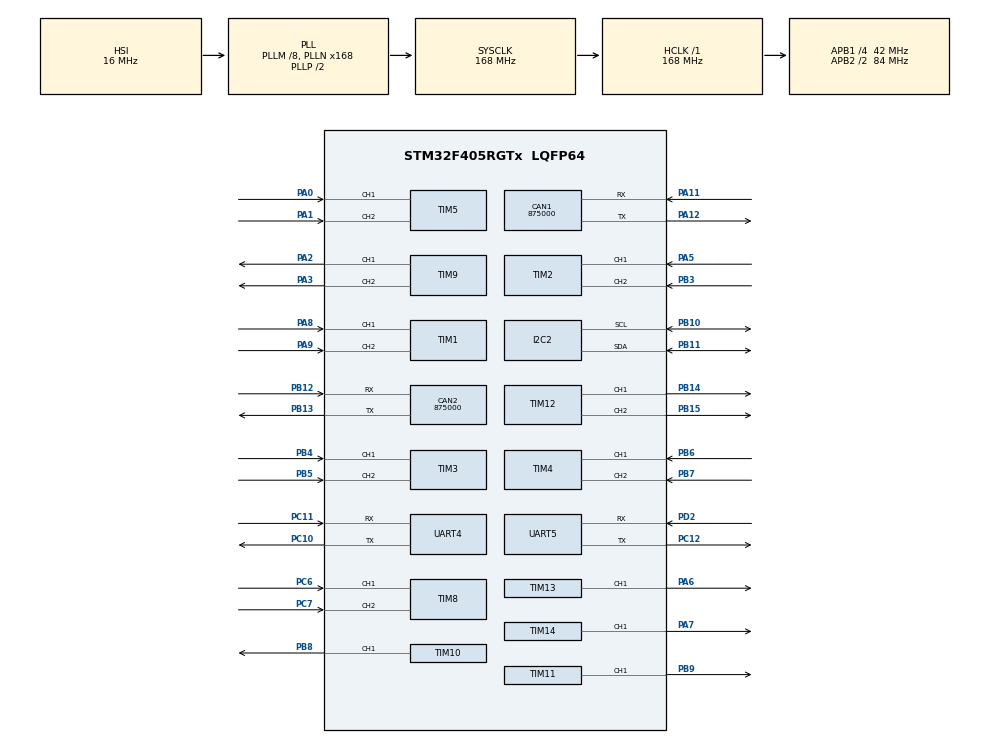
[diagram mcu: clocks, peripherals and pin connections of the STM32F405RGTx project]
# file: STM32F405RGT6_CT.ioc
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CAN1.CalculateBaudRate=875000
CAN1.CalculateTimeBit=1142
CAN1.CalculateTimeQuantum=380.95238095238096
CAN2.CalculateBaudRate=875000
CAN2.CalculateTimeBit=1142
CAN2.CalculateTimeQuantum=380.95238095238096
FREERTOS.Tasks01=defaultTask,24,128,StartDefaultTask,Default,NULL,Dynamic,NULL,NULL
Mcu.Family=STM32F4
Mcu.Name=STM32F405RGTx
Mcu.Package=LQFP64
NVIC.PriorityGroup=NVIC_PRIORITYGROUP_4
NVIC.TIM6_DAC_IRQn=true\:15\:0\:false\:false\:true\:false\:false\:true\:true
NVIC.TimeBase=TIM6_DAC_IRQn
NVIC.TimeBaseIP=TIM6
PA0-WKUP.Signal=S_TIM5_CH1
PA1.Signal=S_TIM5_CH2
PA11.Mode=CAN_Activate
PA11.Signal=CAN1_RX
PA12.Mode=CAN_Activate
PA12.Signal=CAN1_TX
PA13.Mode=Serial_Wire
PA13.Signal=SYS_JTMS-SWDIO
PA14.Mode=Serial_Wire
PA14.Signal=SYS_JTCK-SWCLK
PA2.Signal=S_TIM9_CH1
PA3.Signal=S_TIM9_CH2
PA5.Signal=S_TIM2_CH1_ETR
PA6.Signal=S_TIM13_CH1
PA7.Signal=S_TIM14_CH1
PA8.Signal=S_TIM1_CH1
PA9.Signal=S_TIM1_CH2
PB10.Mode=I2C
PB10.Signal=I2C2_SCL
PB11.Mode=I2C
PB11.Signal=I2C2_SDA
PB12.Mode=CAN_Activate
PB12.Signal=CAN2_RX
PB13.Mode=CAN_Activate
PB13.Signal=CAN2_TX
PB14.Signal=S_TIM12_CH1
PB15.Signal=S_TIM12_CH2
PB3.Signal=S_TIM2_CH2
PB4.Signal=S_TIM3_CH1
PB5.Signal=S_TIM3_CH2
PB6.Signal=S_TIM4_CH1
PB7.Signal=S_TIM4_CH2
PB8.Signal=S_TIM10_CH1
PB9.Signal=S_TIM11_CH1
PC10.Mode=Asynchronous
PC10.Signal=UART4_TX
PC11.Mode=Asynchronous
PC11.Signal=UART4_RX
PC12.Mode=Asynchronous
PC12.Signal=UART5_TX
PC6.Signal=S_TIM8_CH1
PC7.Signal=S_TIM8_CH2
PD2.Mode=Asynchronous
PD2.Signal=UART5_RX
PH0-OSC_IN.Mode=HSE-External-Oscillator
PH0-OSC_IN.Signal=RCC_OSC_IN
PH1-OSC_OUT.Mode=HSE-External-Oscillator
PH1-OSC_OUT.Signal=RCC_OSC_OUT
ProjectManager.HeapSize=0x200
ProjectManager.StackSize=0x400
ProjectManager.TargetToolchain=CMake
RCC.48MHZClocksFreq_Value=84000000
RCC.AHBFreq_Value=168000000
RCC.APB1CLKDivider=RCC_HCLK_DIV4
RCC.APB1Freq_Value=42000000
RCC.APB1TimFreq_Value=84000000
RCC.APB2CLKDivider=RCC_HCLK_DIV2
RCC.APB2Freq_Value=84000000
RCC.APB2TimFreq_Value=168000000
RCC.CortexFreq_Value=168000000
RCC.HCLKFreq_Value=168000000
RCC.HSE_VALUE=8000000
RCC.HSI_VALUE=16000000
RCC.LSE_VALUE=32768
RCC.PLLM=8
RCC.PLLN=168
RCC.SYSCLKFreq_VALUE=168000000
RCC.SYSCLKSource=RCC_SYSCLKSOURCE_PLLCLK
RCC.VCOOutputFreq_Value=336000000
SH.S_TIM10_CH1.0=TIM10_CH1,PWM Generation1 CH1
SH.S_TIM11_CH1.0=TIM11_CH1,PWM Generation1 CH1
SH.S_TIM12_CH1.0=TIM12_CH1,PWM Generation1 CH1
SH.S_TIM12_CH2.0=TIM12_CH2,PWM Generation2 CH2
SH.S_TIM13_CH1.0=TIM13_CH1,PWM Generation1 CH1
SH.S_TIM14_CH1.0=TIM14_CH1,PWM Generation1 CH1
SH.S_TIM1_CH1.0=TIM1_CH1,Encoder_Interface
SH.S_TIM1_CH2.0=TIM1_CH2,Encoder_Interface
SH.S_TIM2_CH1_ETR.0=TIM2_CH1,Encoder_Interface
SH.S_TIM2_CH2.0=TIM2_CH2,Encoder_Interface
SH.S_TIM3_CH1.0=TIM3_CH1,Encoder_Interface
SH.S_TIM3_CH2.0=TIM3_CH2,Encoder_Interface
SH.S_TIM4_CH1.0=TIM4_CH1,Encoder_Interface
SH.S_TIM4_CH2.0=TIM4_CH2,Encoder_Interface
SH.S_TIM5_CH1.0=TIM5_CH1,Encoder_Interface
SH.S_TIM5_CH2.0=TIM5_CH2,Encoder_Interface
SH.S_TIM8_CH1.0=TIM8_CH1,Encoder_Interface
SH.S_TIM8_CH2.0=TIM8_CH2,Encoder_Interface
SH.S_TIM9_CH1.0=TIM9_CH1,PWM Generation1 CH1
SH.S_TIM9_CH2.0=TIM9_CH2,PWM Generation2 CH2
TIM10.Channel=TIM_CHANNEL_1
TIM11.Channel=TIM_CHANNEL_1
TIM12.Channel-PWM\ Generation1\ CH1=TIM_CHANNEL_1
TIM12.Channel-PWM\ Generation2\ CH2=TIM_CHANNEL_2
TIM13.Channel=TIM_CHANNEL_1
TIM14.Channel=TIM_CHANNEL_1
TIM9.Channel-PWM\ Generation1\ CH1=TIM_CHANNEL_1
TIM9.Channel-PWM\ Generation2\ CH2=TIM_CHANNEL_2
UART4.VirtualMode=Asynchronous
UART5.VirtualMode=Asynchronous
VP_FREERTOS_VS_CMSIS_V2.Mode=CMSIS_V2
VP_SYS_VS_tim6.Mode=TIM6
VP_TIM10_VS_ClockSourceINT.Mode=Enable_Timer
VP_TIM11_VS_ClockSourceINT.Mode=Enable_Timer
VP_TIM12_VS_ClockSourceINT.Mode=Internal
VP_TIM13_VS_ClockSourceINT.Mode=Enable_Timer
VP_TIM14_VS_ClockSourceINT.Mode=Enable_Timer
VP_TIM9_VS_ClockSourceINT.Mode=Internal
board=custom

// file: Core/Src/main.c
/* USER CODE BEGIN Header */
/**
  ******************************************************************************
  * @file           : main.c
  * @brief          : Main program body
  ******************************************************************************
  * @attention
  *
  * Copyright (c) 2026 STMicroelectronics.
  * All rights reserved.
  *
  * This software is licensed under terms that can be found in the LICENSE file
  * in the root directory of this software component.
  * If no LICENSE file comes with this software, it is provided AS-IS.
  *
  ******************************************************************************
  */
/* USER CODE END Header */
#include "main.h"
#include "cmsis_os.h"

CAN_HandleTypeDef hcan1;
CAN_HandleTypeDef hcan2;

I2C_HandleTypeDef hi2c2;

TIM_HandleTypeDef htim1;
TIM_HandleTypeDef htim2;
TIM_HandleTypeDef htim3;
TIM_HandleTypeDef htim4;
TIM_HandleTypeDef htim5;
TIM_HandleTypeDef htim8;
TIM_HandleTypeDef htim9;
TIM_HandleTypeDef htim10;
TIM_HandleTypeDef htim11;
TIM_HandleTypeDef htim12;
TIM_HandleTypeDef htim13;
TIM_HandleTypeDef htim14;

UART_HandleTypeDef huart4;
UART_HandleTypeDef huart5;

/* Definitions for defaultTask */
osThreadId_t defaultTaskHandle;
const osThreadAttr_t defaultTask_attributes = {
  .name = "defaultTask",
  .stack_size = 128 * 4,
  .priority = (osPriority_t) osPriorityNormal,
};

void SystemClock_Config(void);
static void MX_GPIO_Init(void);
static void MX_CAN1_Init(void);
static void MX_CAN2_Init(void);
static void MX_I2C2_Init(void);
static void MX_TIM1_Init(void);
static void MX_TIM2_Init(void);
static void MX_TIM3_Init(void);
static void MX_TIM4_Init(void);
static void MX_TIM5_Init(void);
static void MX_TIM8_Init(void);
static void MX_TIM9_Init(void);
static void MX_TIM10_Init(void);
static void MX_TIM11_Init(void);
static void MX_TIM12_Init(void);
static void MX_TIM13_Init(void);
static void MX_TIM14_Init(void);
static void MX_UART4_Init(void);
static void MX_UART5_Init(void);
void StartDefaultTask(void *argument);

int main(void)
{

  /* MCU Configuration--------------------------------------------------------*/

  /* Reset of all peripherals, Initializes the Flash interface and the Systick. */
  HAL_Init();

  /* Configure the system clock */
  SystemClock_Config();

  /* Initialize all configured peripherals */
  MX_GPIO_Init();
  MX_CAN1_Init();
  MX_CAN2_Init();
  MX_I2C2_Init();
  MX_TIM1_Init();
  MX_TIM2_Init();
  MX_TIM3_Init();
  MX_TIM4_Init();
  MX_TIM5_Init();
  MX_TIM8_Init();
  MX_TIM9_Init();
  MX_TIM10_Init();
  MX_TIM11_Init();
  MX_TIM12_Init();
  MX_TIM13_Init();
  MX_TIM14_Init();
  MX_UART4_Init();
  MX_UART5_Init();

  /* Init scheduler */
  osKernelInitialize();

  /* Create the thread(s) */
  /* creation of defaultTask */
  defaultTaskHandle = osThreadNew(StartDefaultTask, NULL, &defaultTask_attributes);

  /* Start scheduler */
  osKernelStart();

  /* We should never get here as control is now taken by the scheduler */

  /* Infinite loop */
  /* USER CODE BEGIN WHILE */
  while (1)
  {
    HAL_GPIO_TogglePin(GPIOC, GPIO_PIN_13);
    HAL_Delay(500);
    /* USER CODE END WHILE */

  }
}

void SystemClock_Config(void)
{
  RCC_OscInitTypeDef RCC_OscInitStruct = {0};
  RCC_ClkInitTypeDef RCC_ClkInitStruct = {0};

  /** Configure the main internal regulator output voltage
  */
  __HAL_RCC_PWR_CLK_ENABLE();
  __HAL_PWR_VOLTAGESCALING_CONFIG(PWR_REGULATOR_VOLTAGE_SCALE1);

  /** Initializes the RCC Oscillators according to the specified parameters
  * in the RCC_OscInitTypeDef structure.
  */
  RCC_OscInitStruct.OscillatorType = RCC_OSCILLATORTYPE_HSI;
  RCC_OscInitStruct.HSIState = RCC_HSI_ON;
  RCC_OscInitStruct.HSICalibrationValue = RCC_HSICALIBRATION_DEFAULT;
  RCC_OscInitStruct.PLL.PLLState = RCC_PLL_ON;
  RCC_OscInitStruct.PLL.PLLSource = RCC_PLLSOURCE_HSI;
  RCC_OscInitStruct.PLL.PLLM = 8;
  RCC_OscInitStruct.PLL.PLLN = 168;
  RCC_OscInitStruct.PLL.PLLP = RCC_PLLP_DIV2;
  RCC_OscInitStruct.PLL.PLLQ = 4;
  if (HAL_RCC_OscConfig(&RCC_OscInitStruct) != HAL_OK)
  {
    Error_Handler();
  }

  /** Initializes the CPU, AHB and APB buses clocks
  */
  RCC_ClkInitStruct.ClockType = RCC_CLOCKTYPE_HCLK|RCC_CLOCKTYPE_SYSCLK
                              |RCC_CLOCKTYPE_PCLK1|RCC_CLOCKTYPE_PCLK2;
  RCC_ClkInitStruct.SYSCLKSource = RCC_SYSCLKSOURCE_PLLCLK;
  RCC_ClkInitStruct.AHBCLKDivider = RCC_SYSCLK_DIV1;
  RCC_ClkInitStruct.APB1CLKDivider = RCC_HCLK_DIV4;
  RCC_ClkInitStruct.APB2CLKDivider = RCC_HCLK_DIV2;

  if (HAL_RCC_ClockConfig(&RCC_ClkInitStruct, FLASH_LATENCY_5) != HAL_OK)
  {
    Error_Handler();
  }
}

static void MX_CAN1_Init(void)
{

  hcan1.Instance = CAN1;
  hcan1.Init.Prescaler = 16;
  hcan1.Init.Mode = CAN_MODE_NORMAL;
  hcan1.Init.SyncJumpWidth = CAN_SJW_1TQ;
  hcan1.Init.TimeSeg1 = CAN_BS1_1TQ;
  hcan1.Init.TimeSeg2 = CAN_BS2_1TQ;
  hcan1.Init.TimeTriggeredMode = DISABLE;
  hcan1.Init.AutoBusOff = DISABLE;
  hcan1.Init.AutoWakeUp = DISABLE;
  hcan1.Init.AutoRetransmission = DISABLE;
  hcan1.Init.ReceiveFifoLocked = DISABLE;
  hcan1.Init.TransmitFifoPriority = DISABLE;
  if (HAL_CAN_Init(&hcan1) != HAL_OK)
  {
    Error_Handler();
  }

}

static void MX_CAN2_Init(void)
{

  hcan2.Instance = CAN2;
  hcan2.Init.Prescaler = 16;
  hcan2.Init.Mode = CAN_MODE_NORMAL;
  hcan2.Init.SyncJumpWidth = CAN_SJW_1TQ;
  hcan2.Init.TimeSeg1 = CAN_BS1_1TQ;
  hcan2.Init.TimeSeg2 = CAN_BS2_1TQ;
  hcan2.Init.TimeTriggeredMode = DISABLE;
  hcan2.Init.AutoBusOff = DISABLE;
  hcan2.Init.AutoWakeUp = DISABLE;
  hcan2.Init.AutoRetransmission = DISABLE;
  hcan2.Init.ReceiveFifoLocked = DISABLE;
  hcan2.Init.TransmitFifoPriority = DISABLE;
  if (HAL_CAN_Init(&hcan2) != HAL_OK)
  {
    Error_Handler();
  }

}

static void MX_I2C2_Init(void)
{

  hi2c2.Instance = I2C2;
  hi2c2.Init.ClockSpeed = 100000;
  hi2c2.Init.DutyCycle = I2C_DUTYCYCLE_2;
  hi2c2.Init.OwnAddress1 = 0;
  hi2c2.Init.AddressingMode = I2C_ADDRESSINGMODE_7BIT;
  hi2c2.Init.DualAddressMode = I2C_DUALADDRESS_DISABLE;
  hi2c2.Init.OwnAddress2 = 0;
  hi2c2.Init.GeneralCallMode = I2C_GENERALCALL_DISABLE;
  hi2c2.Init.NoStretchMode = I2C_NOSTRETCH_DISABLE;
  if (HAL_I2C_Init(&hi2c2) != HAL_OK)
  {
    Error_Handler();
  }

}

static void MX_TIM1_Init(void)
{

  TIM_Encoder_InitTypeDef sConfig = {0};
  TIM_MasterConfigTypeDef sMasterConfig = {0};

  htim1.Instance = TIM1;
  htim1.Init.Prescaler = 0;
  htim1.Init.CounterMode = TIM_COUNTERMODE_UP;
  htim1.Init.Period = 65535;
  htim1.Init.ClockDivision = TIM_CLOCKDIVISION_DIV1;
  htim1.Init.RepetitionCounter = 0;
  htim1.Init.AutoReloadPreload = TIM_AUTORELOAD_PRELOAD_DISABLE;
  sConfig.EncoderMode = TIM_ENCODERMODE_TI1;
  sConfig.IC1Polarity = TIM_ICPOLARITY_RISING;
  sConfig.IC1Selection = TIM_ICSELECTION_DIRECTTI;
  sConfig.IC1Prescaler = TIM_ICPSC_DIV1;
  sConfig.IC1Filter = 0;
  sConfig.IC2Polarity = TIM_ICPOLARITY_RISING;
  sConfig.IC2Selection = TIM_ICSELECTION_DIRECTTI;
  sConfig.IC2Prescaler = TIM_ICPSC_DIV1;
  sConfig.IC2Filter = 0;
  if (HAL_TIM_Encoder_Init(&htim1, &sConfig) != HAL_OK)
  {
    Error_Handler();
  }
  sMasterConfig.MasterOutputTrigger = TIM_TRGO_RESET;
  sMasterConfig.MasterSlaveMode = TIM_MASTERSLAVEMODE_DISABLE;
  if (HAL_TIMEx_MasterConfigSynchronization(&htim1, &sMasterConfig) != HAL_OK)
  {
    Error_Handler();
  }

}

static void MX_TIM2_Init(void)
{

  TIM_Encoder_InitTypeDef sConfig = {0};
  TIM_MasterConfigTypeDef sMasterConfig = {0};

  htim2.Instance = TIM2;
  htim2.Init.Prescaler = 0;
  htim2.Init.CounterMode = TIM_COUNTERMODE_UP;
  htim2.Init.Period = 4294967295;
  htim2.Init.ClockDivision = TIM_CLOCKDIVISION_DIV1;
  htim2.Init.AutoReloadPreload = TIM_AUTORELOAD_PRELOAD_DISABLE;
  sConfig.EncoderMode = TIM_ENCODERMODE_TI1;
  sConfig.IC1Polarity = TIM_ICPOLARITY_RISING;
  sConfig.IC1Selection = TIM_ICSELECTION_DIRECTTI;
  sConfig.IC1Prescaler = TIM_ICPSC_DIV1;
  sConfig.IC1Filter = 0;
  sConfig.IC2Polarity = TIM_ICPOLARITY_RISING;
  sConfig.IC2Selection = TIM_ICSELECTION_DIRECTTI;
  sConfig.IC2Prescaler = TIM_ICPSC_DIV1;
  sConfig.IC2Filter = 0;
  if (HAL_TIM_Encoder_Init(&htim2, &sConfig) != HAL_OK)
  {
    Error_Handler();
  }
  sMasterConfig.MasterOutputTrigger = TIM_TRGO_RESET;
  sMasterConfig.MasterSlaveMode = TIM_MASTERSLAVEMODE_DISABLE;
  if (HAL_TIMEx_MasterConfigSynchronization(&htim2, &sMasterConfig) != HAL_OK)
  {
    Error_Handler();
  }

}

static void MX_TIM3_Init(void)
{

  TIM_Encoder_InitTypeDef sConfig = {0};
  TIM_MasterConfigTypeDef sMasterConfig = {0};

  htim3.Instance = TIM3;
  htim3.Init.Prescaler = 0;
  htim3.Init.CounterMode = TIM_COUNTERMODE_UP;
  htim3.Init.Period = 65535;
  htim3.Init.ClockDivision = TIM_CLOCKDIVISION_DIV1;
  htim3.Init.AutoReloadPreload = TIM_AUTORELOAD_PRELOAD_DISABLE;
  sConfig.EncoderMode = TIM_ENCODERMODE_TI1;
  sConfig.IC1Polarity = TIM_ICPOLARITY_RISING;
  sConfig.IC1Selection = TIM_ICSELECTION_DIRECTTI;
  sConfig.IC1Prescaler = TIM_ICPSC_DIV1;
  sConfig.IC1Filter = 0;
  sConfig.IC2Polarity = TIM_ICPOLARITY_RISING;
  sConfig.IC2Selection = TIM_ICSELECTION_DIRECTTI;
  sConfig.IC2Prescaler = TIM_ICPSC_DIV1;
  sConfig.IC2Filter = 0;
  if (HAL_TIM_Encoder_Init(&htim3, &sConfig) != HAL_OK)
  {
    Error_Handler();
  }
  sMasterConfig.MasterOutputTrigger = TIM_TRGO_RESET;
  sMasterConfig.MasterSlaveMode = TIM_MASTERSLAVEMODE_DISABLE;
  if (HAL_TIMEx_MasterConfigSynchronization(&htim3, &sMasterConfig) != HAL_OK)
  {
    Error_Handler();
  }

}

static void MX_TIM4_Init(void)
{

  TIM_Encoder_InitTypeDef sConfig = {0};
  TIM_MasterConfigTypeDef sMasterConfig = {0};

  htim4.Instance = TIM4;
  htim4.Init.Prescaler = 0;
  htim4.Init.CounterMode = TIM_COUNTERMODE_UP;
  htim4.Init.Period = 65535;
  htim4.Init.ClockDivision = TIM_CLOCKDIVISION_DIV1;
  htim4.Init.AutoReloadPreload = TIM_AUTORELOAD_PRELOAD_DISABLE;
  sConfig.EncoderMode = TIM_ENCODERMODE_TI1;
  sConfig.IC1Polarity = TIM_ICPOLARITY_RISING;
  sConfig.IC1Selection = TIM_ICSELECTION_DIRECTTI;
  sConfig.IC1Prescaler = TIM_ICPSC_DIV1;
  sConfig.IC1Filter = 0;
  sConfig.IC2Polarity = TIM_ICPOLARITY_RISING;
  sConfig.IC2Selection = TIM_ICSELECTION_DIRECTTI;
  sConfig.IC2Prescaler = TIM_ICPSC_DIV1;
  sConfig.IC2Filter = 0;
  if (HAL_TIM_Encoder_Init(&htim4, &sConfig) != HAL_OK)
  {
    Error_Handler();
  }
  sMasterConfig.MasterOutputTrigger = TIM_TRGO_RESET;
  sMasterConfig.MasterSlaveMode = TIM_MASTERSLAVEMODE_DISABLE;
  if (HAL_TIMEx_MasterConfigSynchronization(&htim4, &sMasterConfig) != HAL_OK)
  {
    Error_Handler();
  }

}

static void MX_TIM5_Init(void)
{

  TIM_Encoder_InitTypeDef sConfig = {0};
  TIM_MasterConfigTypeDef sMasterConfig = {0};

  htim5.Instance = TIM5;
  htim5.Init.Prescaler = 0;
  htim5.Init.CounterMode = TIM_COUNTERMODE_UP;
  htim5.Init.Period = 4294967295;
  htim5.Init.ClockDivision = TIM_CLOCKDIVISION_DIV1;
  htim5.Init.AutoReloadPreload = TIM_AUTORELOAD_PRELOAD_DISABLE;
  sConfig.EncoderMode = TIM_ENCODERMODE_TI1;
  sConfig.IC1Polarity = TIM_ICPOLARITY_RISING;
  sConfig.IC1Selection = TIM_ICSELECTION_DIRECTTI;
  sConfig.IC1Prescaler = TIM_ICPSC_DIV1;
  sConfig.IC1Filter = 0;
  sConfig.IC2Polarity = TIM_ICPOLARITY_RISING;
  sConfig.IC2Selection = TIM_ICSELECTION_DIRECTTI;
  sConfig.IC2Prescaler = TIM_ICPSC_DIV1;
  sConfig.IC2Filter = 0;
  if (HAL_TIM_Encoder_Init(&htim5, &sConfig) != HAL_OK)
  {
    Error_Handler();
  }
  sMasterConfig.MasterOutputTrigger = TIM_TRGO_RESET;
  sMasterConfig.MasterSlaveMode = TIM_MASTERSLAVEMODE_DISABLE;
  if (HAL_TIMEx_MasterConfigSynchronization(&htim5, &sMasterConfig) != HAL_OK)
  {
    Error_Handler();
  }

}

static void MX_TIM8_Init(void)
{

  TIM_Encoder_InitTypeDef sConfig = {0};
  TIM_MasterConfigTypeDef sMasterConfig = {0};

  htim8.Instance = TIM8;
  htim8.Init.Prescaler = 0;
  htim8.Init.CounterMode = TIM_COUNTERMODE_UP;
  htim8.Init.Period = 65535;
  htim8.Init.ClockDivision = TIM_CLOCKDIVISION_DIV1;
  htim8.Init.RepetitionCounter = 0;
  htim8.Init.AutoReloadPreload = TIM_AUTORELOAD_PRELOAD_DISABLE;
  sConfig.EncoderMode = TIM_ENCODERMODE_TI1;
  sConfig.IC1Polarity = TIM_ICPOLARITY_RISING;
  sConfig.IC1Selection = TIM_ICSELECTION_DIRECTTI;
  sConfig.IC1Prescaler = TIM_ICPSC_DIV1;
  sConfig.IC1Filter = 0;
  sConfig.IC2Polarity = TIM_ICPOLARITY_RISING;
  sConfig.IC2Selection = TIM_ICSELECTION_DIRECTTI;
  sConfig.IC2Prescaler = TIM_ICPSC_DIV1;
  sConfig.IC2Filter = 0;
  if (HAL_TIM_Encoder_Init(&htim8, &sConfig) != HAL_OK)
  {
    Error_Handler();
  }
  sMasterConfig.MasterOutputTrigger = TIM_TRGO_RESET;
  sMasterConfig.MasterSlaveMode = TIM_MASTERSLAVEMODE_DISABLE;
  if (HAL_TIMEx_MasterConfigSynchronization(&htim8, &sMasterConfig) != HAL_OK)
  {
    Error_Handler();
  }

}

static void MX_TIM9_Init(void)
{

  TIM_ClockConfigTypeDef sClockSourceConfig = {0};
  TIM_OC_InitTypeDef sConfigOC = {0};

  htim9.Instance = TIM9;
  htim9.Init.Prescaler = 0;
  htim9.Init.CounterMode = TIM_COUNTERMODE_UP;
  htim9.Init.Period = 65535;
  htim9.Init.ClockDivision = TIM_CLOCKDIVISION_DIV1;
  htim9.Init.AutoReloadPreload = TIM_AUTORELOAD_PRELOAD_DISABLE;
  if (HAL_TIM_Base_Init(&htim9) != HAL_OK)
  {
    Error_Handler();
  }
  sClockSourceConfig.ClockSource = TIM_CLOCKSOURCE_INTERNAL;
  if (HAL_TIM_ConfigClockSource(&htim9, &sClockSourceConfig) != HAL_OK)
  {
    Error_Handler();
  }
  if (HAL_TIM_PWM_Init(&htim9) != HAL_OK)
  {
    Error_Handler();
  }
  sConfigOC.OCMode = TIM_OCMODE_PWM1;
  sConfigOC.Pulse = 0;
  sConfigOC.OCPolarity = TIM_OCPOLARITY_HIGH;
  sConfigOC.OCFastMode = TIM_OCFAST_DISABLE;
  if (HAL_TIM_PWM_ConfigChannel(&htim9, &sConfigOC, TIM_CHANNEL_1) != HAL_OK)
  {
    Error_Handler();
  }
  if (HAL_TIM_PWM_ConfigChannel(&htim9, &sConfigOC, TIM_CHANNEL_2) != HAL_OK)
  {
    Error_Handler();
  }
  HAL_TIM_MspPostInit(&htim9);

}

static void MX_TIM10_Init(void)
{

  TIM_OC_InitTypeDef sConfigOC = {0};

  htim10.Instance = TIM10;
  htim10.Init.Prescaler = 0;
  htim10.Init.CounterMode = TIM_COUNTERMODE_UP;
  htim10.Init.Period = 65535;
  htim10.Init.ClockDivision = TIM_CLOCKDIVISION_DIV1;
  htim10.Init.AutoReloadPreload = TIM_AUTORELOAD_PRELOAD_DISABLE;
  if (HAL_TIM_Base_Init(&htim10) != HAL_OK)
  {
    Error_Handler();
  }
  if (HAL_TIM_PWM_Init(&htim10) != HAL_OK)
  {
    Error_Handler();
  }
  sConfigOC.OCMode = TIM_OCMODE_PWM1;
  sConfigOC.Pulse = 0;
  sConfigOC.OCPolarity = TIM_OCPOLARITY_HIGH;
  sConfigOC.OCFastMode = TIM_OCFAST_DISABLE;
  if (HAL_TIM_PWM_ConfigChannel(&htim10, &sConfigOC, TIM_CHANNEL_1) != HAL_OK)
  {
    Error_Handler();
  }
  HAL_TIM_MspPostInit(&htim10);

}

static void MX_TIM11_Init(void)
{

  TIM_OC_InitTypeDef sConfigOC = {0};

  htim11.Instance = TIM11;
  htim11.Init.Prescaler = 0;
  htim11.Init.CounterMode = TIM_COUNTERMODE_UP;
  htim11.Init.Period = 65535;
  htim11.Init.ClockDivision = TIM_CLOCKDIVISION_DIV1;
  htim11.Init.AutoReloadPreload = TIM_AUTORELOAD_PRELOAD_DISABLE;
  if (HAL_TIM_Base_Init(&htim11) != HAL_OK)
  {
    Error_Handler();
  }
  if (HAL_TIM_PWM_Init(&htim11) != HAL_OK)
  {
    Error_Handler();
  }
  sConfigOC.OCMode = TIM_OCMODE_PWM1;
  sConfigOC.Pulse = 0;
  sConfigOC.OCPolarity = TIM_OCPOLARITY_HIGH;
  sConfigOC.OCFastMode = TIM_OCFAST_DISABLE;
  if (HAL_TIM_PWM_ConfigChannel(&htim11, &sConfigOC, TIM_CHANNEL_1) != HAL_OK)
  {
    Error_Handler();
  }
  HAL_TIM_MspPostInit(&htim11);

}

static void MX_TIM12_Init(void)
{

  TIM_ClockConfigTypeDef sClockSourceConfig = {0};
  TIM_OC_InitTypeDef sConfigOC = {0};

  htim12.Instance = TIM12;
  htim12.Init.Prescaler = 0;
  htim12.Init.CounterMode = TIM_COUNTERMODE_UP;
  htim12.Init.Period = 65535;
  htim12.Init.ClockDivision = TIM_CLOCKDIVISION_DIV1;
  htim12.Init.AutoReloadPreload = TIM_AUTORELOAD_PRELOAD_DISABLE;
  if (HAL_TIM_Base_Init(&htim12) != HAL_OK)
  {
    Error_Handler();
  }
  sClockSourceConfig.ClockSource = TIM_CLOCKSOURCE_INTERNAL;
  if (HAL_TIM_ConfigClockSource(&htim12, &sClockSourceConfig) != HAL_OK)
  {
    Error_Handler();
  }
  if (HAL_TIM_PWM_Init(&htim12) != HAL_OK)
  {
    Error_Handler();
  }
  sConfigOC.OCMode = TIM_OCMODE_PWM1;
  sConfigOC.Pulse = 0;
  sConfigOC.OCPolarity = TIM_OCPOLARITY_HIGH;
  sConfigOC.OCFastMode = TIM_OCFAST_DISABLE;
  if (HAL_TIM_PWM_ConfigChannel(&htim12, &sConfigOC, TIM_CHANNEL_1) != HAL_OK)
  {
    Error_Handler();
  }
  if (HAL_TIM_PWM_ConfigChannel(&htim12, &sConfigOC, TIM_CHANNEL_2) != HAL_OK)
  {
    Error_Handler();
  }
  HAL_TIM_MspPostInit(&htim12);

}

static void MX_TIM13_Init(void)
{

  TIM_OC_InitTypeDef sConfigOC = {0};

  htim13.Instance = TIM13;
  htim13.Init.Prescaler = 0;
  htim13.Init.CounterMode = TIM_COUNTERMODE_UP;
  htim13.Init.Period = 65535;
  htim13.Init.ClockDivision = TIM_CLOCKDIVISION_DIV1;
  htim13.Init.AutoReloadPreload = TIM_AUTORELOAD_PRELOAD_DISABLE;
  if (HAL_TIM_Base_Init(&htim13) != HAL_OK)
  {
    Error_Handler();
  }
  if (HAL_TIM_PWM_Init(&htim13) != HAL_OK)
  {
    Error_Handler();
  }
  sConfigOC.OCMode = TIM_OCMODE_PWM1;
  sConfigOC.Pulse = 0;
  sConfigOC.OCPolarity = TIM_OCPOLARITY_HIGH;
  sConfigOC.OCFastMode = TIM_OCFAST_DISABLE;
  if (HAL_TIM_PWM_ConfigChannel(&htim13, &sConfigOC, TIM_CHANNEL_1) != HAL_OK)
  {
    Error_Handler();
  }
  HAL_TIM_MspPostInit(&htim13);

}

static void MX_TIM14_Init(void)
{

  TIM_OC_InitTypeDef sConfigOC = {0};

  htim14.Instance = TIM14;
  htim14.Init.Prescaler = 0;
  htim14.Init.CounterMode = TIM_COUNTERMODE_UP;
  htim14.Init.Period = 65535;
  htim14.Init.ClockDivision = TIM_CLOCKDIVISION_DIV1;
  htim14.Init.AutoReloadPreload = TIM_AUTORELOAD_PRELOAD_DISABLE;
  if (HAL_TIM_Base_Init(&htim14) != HAL_OK)
  {
    Error_Handler();
  }
  if (HAL_TIM_PWM_Init(&htim14) != HAL_OK)
  {
    Error_Handler();
  }
  sConfigOC.OCMode = TIM_OCMODE_PWM1;
  sConfigOC.Pulse = 0;
  sConfigOC.OCPolarity = TIM_OCPOLARITY_HIGH;
  sConfigOC.OCFastMode = TIM_OCFAST_DISABLE;
  if (HAL_TIM_PWM_ConfigChannel(&htim14, &sConfigOC, TIM_CHANNEL_1) != HAL_OK)
  {
    Error_Handler();
  }
  HAL_TIM_MspPostInit(&htim14);

}

static void MX_UART4_Init(void)
{

  huart4.Instance = UART4;
  huart4.Init.BaudRate = 115200;
  huart4.Init.WordLength = UART_WORDLENGTH_8B;
  huart4.Init.StopBits = UART_STOPBITS_1;
  huart4.Init.Parity = UART_PARITY_NONE;
  huart4.Init.Mode = UART_MODE_TX_RX;
  huart4.Init.HwFlowCtl = UART_HWCONTROL_NONE;
  huart4.Init.OverSampling = UART_OVERSAMPLING_16;
  if (HAL_UART_Init(&huart4) != HAL_OK)
  {
    Error_Handler();
  }

}

static void MX_UART5_Init(void)
{

  huart5.Instance = UART5;
  huart5.Init.BaudRate = 115200;
  huart5.Init.WordLength = UART_WORDLENGTH_8B;
  huart5.Init.StopBits = UART_STOPBITS_1;
  huart5.Init.Parity = UART_PARITY_NONE;
  huart5.Init.Mode = UART_MODE_TX_RX;
  huart5.Init.HwFlowCtl = UART_HWCONTROL_NONE;
  huart5.Init.OverSampling = UART_OVERSAMPLING_16;
  if (HAL_UART_Init(&huart5) != HAL_OK)
  {
    Error_Handler();
  }

}

static void MX_GPIO_Init(void)
{

  /* GPIO Ports Clock Enable */
  __HAL_RCC_GPIOH_CLK_ENABLE();
  __HAL_RCC_GPIOA_CLK_ENABLE();
  __HAL_RCC_GPIOB_CLK_ENABLE();
  __HAL_RCC_GPIOC_CLK_ENABLE();
  __HAL_RCC_GPIOD_CLK_ENABLE();

}

void StartDefaultTask(void *argument)
{
  for(;;)
  {
    osDelay(1);
  }
}

void HAL_TIM_PeriodElapsedCallback(TIM_HandleTypeDef *htim)
{
  if (htim->Instance == TIM6)
  {
    HAL_IncTick();
  }
}

void Error_Handler(void)
{
  __disable_irq();
  while (1)
  {
  }
}
